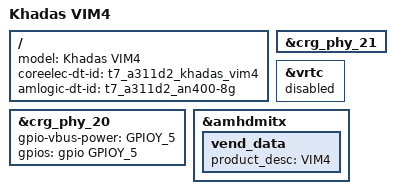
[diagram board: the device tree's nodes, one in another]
#include "t7_a311d2_an400_drm_hdmitx_debian.dts"
#include "coreelec_t7_common.dtsi"
#include "a311d2_khadas_vim4_base.dtsi"

/ {
	model = "Khadas VIM4";
	coreelec-dt-id = "t7_a311d2_khadas_vim4";
	amlogic-dt-id = "t7_a311d2_an400-8g";
};

&crg_phy_20 {
	gpio-vbus-power = "GPIOY_5";
	gpios = <&gpio GPIOY_5 GPIO_ACTIVE_HIGH>;
};

&crg_phy_21 {
	/delete-property/ gpio-vbus-power;
	/delete-property/ gpios;
};

&vrtc {
	status = "disabled";
};

&amhdmitx {
	vend_data {
		product_desc = "VIM4";
	};
};
